AUTOSAR XML (schema 00049)
package /vector/adas_platform
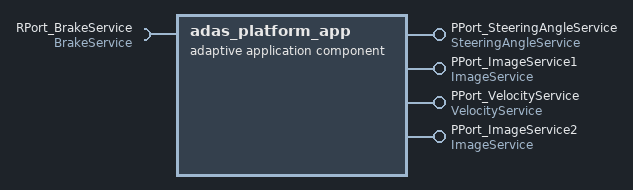
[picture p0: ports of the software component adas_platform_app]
  adaptive application sw component type adas_platform_app
    require port RPort_BrakeService: required-interface=BrakeService
    4 x provide port:
      PPort_SteeringAngleService: provided-interface=SteeringAngleService
      PPort_ImageService1: provided-interface=ImageService
      PPort_VelocityService: provided-interface=VelocityService
      PPort_ImageService2: provided-interface=ImageService
  executable adas_platform: category=APPLICATION_LEVEL, version=1.0.0
    root sw component prototype RootSwComponentPrototype: application-type=adas_platform_app
  process design adas_platform_process_design: executable=adas_platform
  process adas_platform_process: design=adas_platform_process_design, executable=adas_platform, state-dependent-startup-config{function-group-state=[MachineFG.Running, MachineFG.Startup], startup-config=adas_demod_startup_config}
    process state machine adas_demo_test_app_processProcessStatesPrototype: type=MachineStates
  software cluster adas_platform_software_cluster: category=PLATFORM_CORE, claimed-function-group=MachineFG, contained-process=adas_platform_process, version=1.0.0
  startup config set adas_platform_startup_config_set
    startup config adas_demod_startup_config: process-arguments=[-c, ./etc/adas_demod-posix.json], scheduling-policy=SCHED_FIFO, scheduling-priority=12
